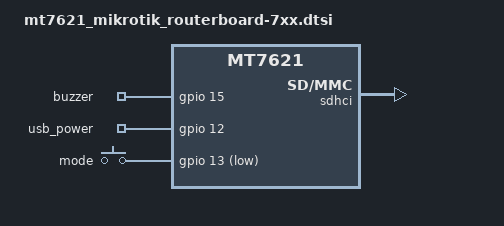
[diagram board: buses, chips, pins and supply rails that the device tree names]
// SPDX-License-Identifier: GPL-2.0-or-later OR MIT

#include "mt7621_mikrotik.dtsi"

/ {
	gpio_export {
		compatible = "gpio-export";
		#size-cells = <0>;

		buzzer {
			/* Beeper requires PWM for frequency selection */
			gpio-export,name = "buzzer";
			gpio-export,output = <0>;
			gpios = <&gpio 15 GPIO_ACTIVE_HIGH>;
		};

		usb_power {
			gpio-export,name = "usb_power";
			gpio-export,output = <1>;
			gpios = <&gpio 12 GPIO_ACTIVE_HIGH>;
		};
	};
};

&keys {
	mode {
		label = "mode";
		gpios = <&gpio 13 GPIO_ACTIVE_LOW>;
		linux,code = <BTN_0>;
	};
};

&partitions {
	partition@40000 {
		compatible = "mikrotik,minor";
		label = "firmware";
		reg = <0x040000 0xfc0000>;
	};
};

&switch0 {
	ports {
		port@0 {
			status = "okay";
			label = "wan";
		};

		port@1 {
			status = "okay";
			label = "lan2";
		};

		port@2 {
			status = "okay";
			label = "lan3";
		};

		port@3 {
			status = "okay";
			label = "lan4";
		};

		port@4 {
			status = "okay";
			label = "lan5";
		};
	};
};

&sdhci {
	status = "okay";
};
